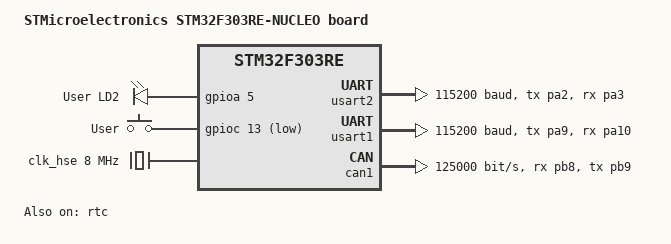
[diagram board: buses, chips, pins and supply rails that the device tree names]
/*
 * Copyright (c) 2020 Paul M. Bendixen
 *
 * SPDX-License-Identifier: Apache-2.0
 */

/dts-v1/;
#include <st/f3/stm32f303Xe.dtsi>
#include <st/f3/stm32f303r(d-e)tx-pinctrl.dtsi>
#include "arduino_r3_connector.dtsi"

/ {
	model = "STMicroelectronics STM32F303RE-NUCLEO board";
	compatible = "st,stm32f303re-nucleo";

	chosen {
		zephyr,console = &usart2;
		zephyr,shell-uart = &usart2;
		zephyr,sram = &sram0;
		zephyr,flash = &flash0;
		zephyr,canbus = &can1;
	};

	leds {
		compatible = "gpio-leds";
		green_led_2: led_2 {
			gpios = <&gpioa 5 GPIO_ACTIVE_HIGH>;
			label = "User LD2";
		};
	};

	gpio_keys {
		compatible = "gpio-keys";
		user_button: button {
			label = "User";
			gpios = <&gpioc 13 GPIO_ACTIVE_LOW>;
		};
	};

	aliases {
		led0 = &green_led_2;
		sw0 = &user_button;
	};
};

&clk_hse {
	hse-bypass;
	clock-frequency = <DT_FREQ_M(8)>; /* STLink 8MHz clock */
	status = "okay";
};

&pll {
	prediv = <1>;
	mul = <9>;
	clocks = <&clk_hse>;
	status = "okay";
};

&rcc {
	clocks = <&pll>;
	clock-frequency = <DT_FREQ_M(72)>;
	ahb-prescaler = <1>;
	apb1-prescaler = <2>;
	apb2-prescaler = <1>;
};

&usart2 {
	pinctrl-0 = <&usart2_tx_pa2 &usart2_rx_pa3>;
	pinctrl-names = "default";
	current-speed = <115200>;
	status = "okay";
};

&usart1 {
	pinctrl-0 = <&usart1_tx_pa9 &usart1_rx_pa10>;
	pinctrl-names = "default";
	current-speed = <115200>;
	status = "okay";
};

&rtc {
	status = "okay";
};

&can1 {
	pinctrl-0 = <&can_rx_pb8 &can_tx_pb9>;
	pinctrl-names = "default";
	bus-speed = <125000>;
	status = "okay";
};
